VERSION ""

NS_ :

BS_:

BU_: Display_Screen Body_Orientation

BO_ 1 GPS: 8 Body_Orientation
 SG_ Body_Speed : 0|8@1+ (0.1,0) [0|25.5] "m/s"  Display_Screen

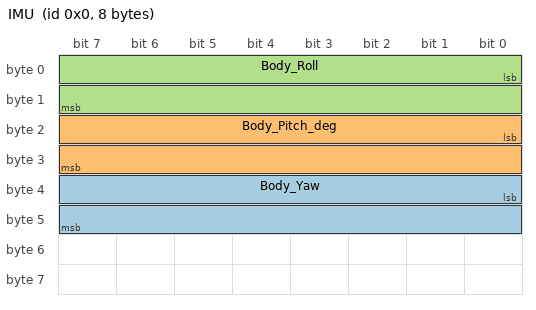
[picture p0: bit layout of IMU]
BO_ 0 IMU: 8 Body_Orientation
 SG_ Body_Yaw : 32|16@1+ (0.1,0) [0|359] "deg"  Display_Screen
 SG_ Body_Pitch_deg : 16|16@1+ (0.1,0) [0|359] "deg"  Display_Screen
 SG_ Body_Roll : 0|16@1+ (0.1,0) [0|359] "deg"  Display_Screen

CM_ SG_ 1 Body_Speed "Velocity of the vehicle body in m/s

Resolution of 0.1 m/s (0.224 mph)";
CM_ SG_ 0 Body_Yaw "Yaw angle of the vehicle body in degrees

Output is an integer to save space

Resolution of 0.1 degrees";
CM_ SG_ 0 Body_Pitch_deg "Pitch angle of the vehicle body in degrees

Output is an integer to save space

Resolution of 0.1 degrees";
CM_ SG_ 0 Body_Roll "Roll angle of the vehicle body in degrees

Output is an integer to save space

Resolution of 0.1 degrees";
BA_DEF_  "BusType" STRING ;
BA_DEF_DEF_  "BusType" "CAN";
